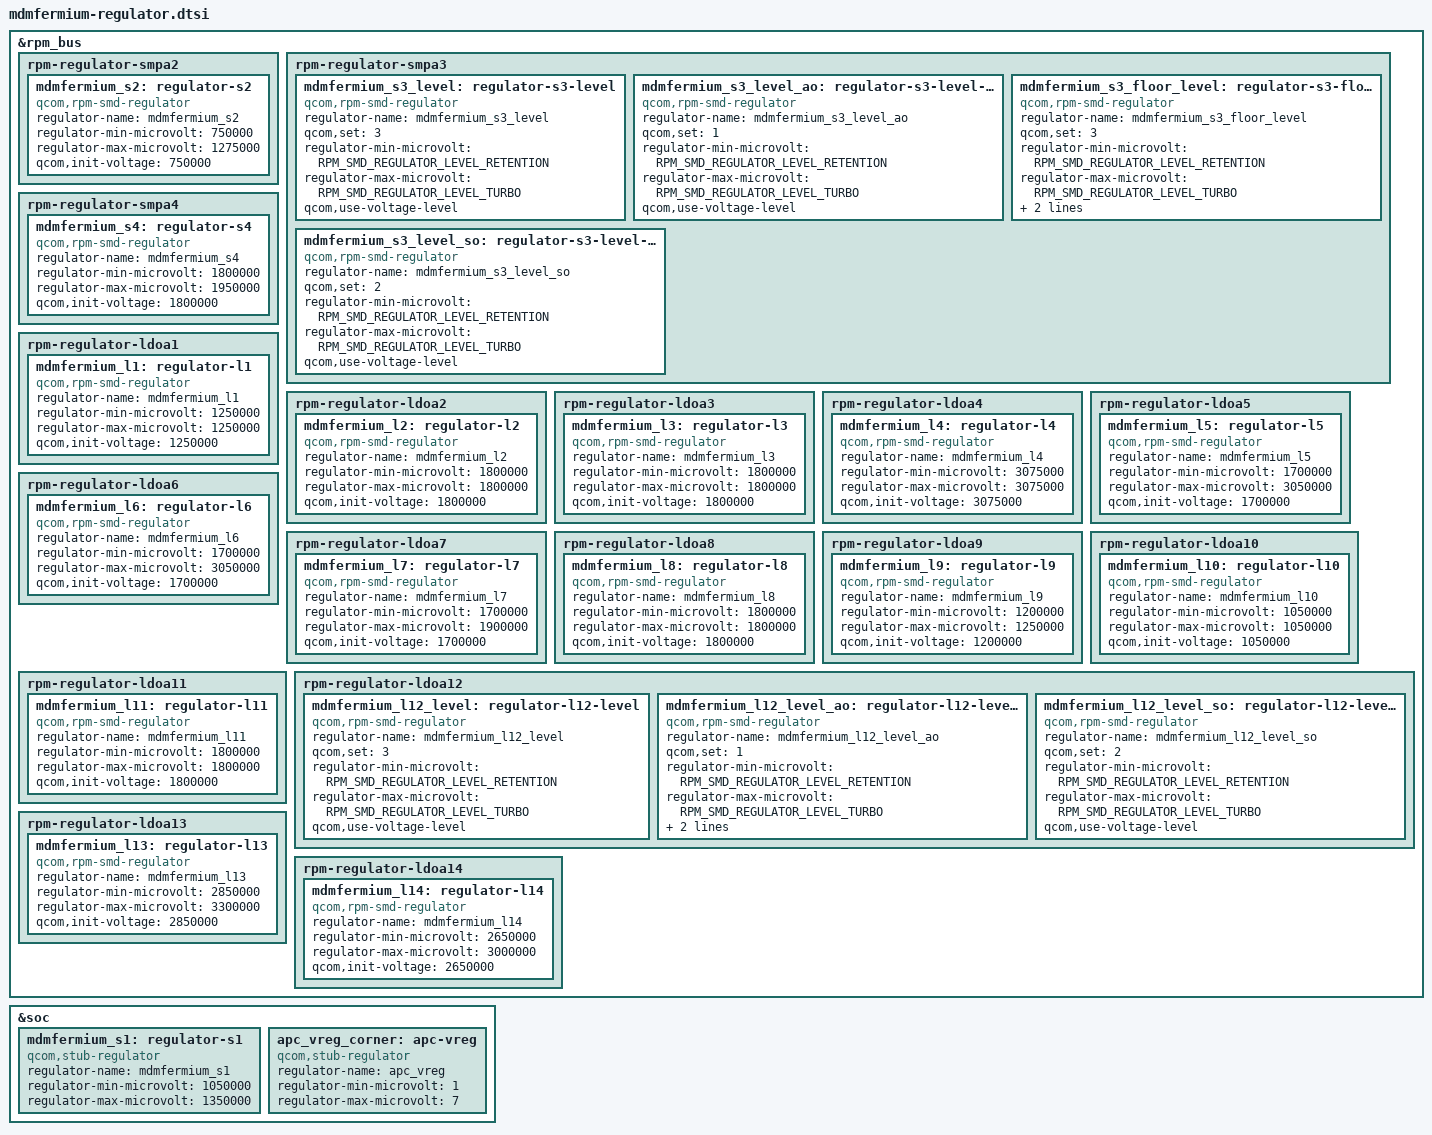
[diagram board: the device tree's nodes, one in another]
/* Copyright (c) 2015, The Linux Foundation. All rights reserved.
 *
 * This program is free software; you can redistribute it and/or modify
 * it under the terms of the GNU General Public License version 2 and
 * only version 2 as published by the Free Software Foundation.
 *
 * This program is distributed in the hope that it will be useful,
 * but WITHOUT ANY WARRANTY; without even the implied warranty of
 * MERCHANTABILITY or FITNESS FOR A PARTICULAR PURPOSE.  See the
 * GNU General Public License for more details.
 */

&rpm_bus {
	rpm-regulator-smpa2 {
		status = "okay";
		mdmfermium_s2: regulator-s2 {
			compatible = "qcom,rpm-smd-regulator";
			regulator-name = "mdmfermium_s2";
			regulator-min-microvolt = <750000>;
			regulator-max-microvolt = <1275000>;
			qcom,init-voltage = <750000>;
			status = "okay";
		};
	};

	/* CX supply */
	rpm-regulator-smpa3 {
		status = "okay";
		mdmfermium_s3_level: regulator-s3-level {
			compatible = "qcom,rpm-smd-regulator";
			regulator-name = "mdmfermium_s3_level";
			qcom,set = <3>;
			regulator-min-microvolt =
					<RPM_SMD_REGULATOR_LEVEL_RETENTION>;
			regulator-max-microvolt =
					<RPM_SMD_REGULATOR_LEVEL_TURBO>;
			qcom,use-voltage-level;
		};

		mdmfermium_s3_level_ao: regulator-s3-level-ao {
			compatible = "qcom,rpm-smd-regulator";
			regulator-name = "mdmfermium_s3_level_ao";
			qcom,set = <1>;
			regulator-min-microvolt =
					<RPM_SMD_REGULATOR_LEVEL_RETENTION>;
			regulator-max-microvolt =
					<RPM_SMD_REGULATOR_LEVEL_TURBO>;
			qcom,use-voltage-level;
		};

		mdmfermium_s3_floor_level: regulator-s3-floor-level {
			compatible = "qcom,rpm-smd-regulator";
			regulator-name = "mdmfermium_s3_floor_level";
			qcom,set = <3>;
			regulator-min-microvolt =
					<RPM_SMD_REGULATOR_LEVEL_RETENTION>;
			regulator-max-microvolt =
					<RPM_SMD_REGULATOR_LEVEL_TURBO>;
			qcom,use-voltage-floor-level;
			qcom,always-send-voltage;
		};

		mdmfermium_s3_level_so: regulator-s3-level-so {
			compatible = "qcom,rpm-smd-regulator";
			regulator-name = "mdmfermium_s3_level_so";
			qcom,set = <2>;
			regulator-min-microvolt =
					<RPM_SMD_REGULATOR_LEVEL_RETENTION>;
			regulator-max-microvolt =
					<RPM_SMD_REGULATOR_LEVEL_TURBO>;
			qcom,use-voltage-level;
		};
	};

	rpm-regulator-smpa4 {
		status = "okay";
		mdmfermium_s4: regulator-s4 {
			compatible = "qcom,rpm-smd-regulator";
			regulator-name = "mdmfermium_s4";
			regulator-min-microvolt = <1800000>;
			regulator-max-microvolt = <1950000>;
			qcom,init-voltage = <1800000>;
			status = "okay";
		};
	};

	rpm-regulator-ldoa1 {
		status = "okay";
		mdmfermium_l1: regulator-l1 {
			compatible = "qcom,rpm-smd-regulator";
			regulator-name = "mdmfermium_l1";
			regulator-min-microvolt = <1250000>;
			regulator-max-microvolt = <1250000>;
			qcom,init-voltage = <1250000>;
			status = "okay";
		};
	};

	rpm-regulator-ldoa2 {
		status = "okay";
		mdmfermium_l2: regulator-l2 {
			compatible = "qcom,rpm-smd-regulator";
			regulator-name = "mdmfermium_l2";
			regulator-min-microvolt = <1800000>;
			regulator-max-microvolt = <1800000>;
			qcom,init-voltage = <1800000>;
			status = "okay";
		};
	};

	rpm-regulator-ldoa3 {
		status = "okay";
		mdmfermium_l3: regulator-l3 {
			compatible = "qcom,rpm-smd-regulator";
			regulator-name = "mdmfermium_l3";
			regulator-min-microvolt = <1800000>;
			regulator-max-microvolt = <1800000>;
			qcom,init-voltage = <1800000>;
			status = "okay";
		};
	};

	rpm-regulator-ldoa4 {
		status = "okay";
		mdmfermium_l4: regulator-l4 {
			compatible = "qcom,rpm-smd-regulator";
			regulator-name = "mdmfermium_l4";
			regulator-min-microvolt = <3075000>;
			regulator-max-microvolt = <3075000>;
			qcom,init-voltage = <3075000>;
			status = "okay";
		};
	};

	rpm-regulator-ldoa5 {
		status = "okay";
		mdmfermium_l5: regulator-l5 {
			compatible = "qcom,rpm-smd-regulator";
			regulator-name = "mdmfermium_l5";
			regulator-min-microvolt = <1700000>;
			regulator-max-microvolt = <3050000>;
			qcom,init-voltage = <1700000>;
			status = "okay";
		};
	};

	rpm-regulator-ldoa6 {
		status = "okay";
		mdmfermium_l6: regulator-l6 {
			compatible = "qcom,rpm-smd-regulator";
			regulator-name = "mdmfermium_l6";
			regulator-min-microvolt = <1700000>;
			regulator-max-microvolt = <3050000>;
			qcom,init-voltage = <1700000>;
			status = "okay";
		};
	};

	rpm-regulator-ldoa7 {
		status = "okay";
		mdmfermium_l7: regulator-l7 {
			compatible = "qcom,rpm-smd-regulator";
			regulator-name = "mdmfermium_l7";
			regulator-min-microvolt = <1700000>;
			regulator-max-microvolt = <1900000>;
			qcom,init-voltage = <1700000>;
			status = "okay";
		};
	};

	rpm-regulator-ldoa8 {
		status = "okay";
		mdmfermium_l8: regulator-l8 {
			compatible = "qcom,rpm-smd-regulator";
			regulator-name = "mdmfermium_l8";
			regulator-min-microvolt = <1800000>;
			regulator-max-microvolt = <1800000>;
			qcom,init-voltage = <1800000>;
			status = "okay";
		};
	};

	rpm-regulator-ldoa9 {
		status = "okay";
		mdmfermium_l9: regulator-l9 {
			compatible = "qcom,rpm-smd-regulator";
			regulator-name = "mdmfermium_l9";
			regulator-min-microvolt = <1200000>;
			regulator-max-microvolt = <1250000>;
			qcom,init-voltage = <1200000>;
			status = "okay";
		};
	};

	rpm-regulator-ldoa10 {
		status = "okay";
		mdmfermium_l10: regulator-l10 {
			compatible = "qcom,rpm-smd-regulator";
			regulator-name = "mdmfermium_l10";
			regulator-min-microvolt = <1050000>;
			regulator-max-microvolt = <1050000>;
			qcom,init-voltage = <1050000>;
			status = "okay";
		};
	};

	rpm-regulator-ldoa11 {
		status = "okay";
		mdmfermium_l11: regulator-l11 {
			compatible = "qcom,rpm-smd-regulator";
			regulator-name = "mdmfermium_l11";
			regulator-min-microvolt = <1800000>;
			regulator-max-microvolt = <1800000>;
			qcom,init-voltage = <1800000>;
			status = "okay";
		};
	};

	/* MX supply */
	rpm-regulator-ldoa12 {
		status = "okay";
		mdmfermium_l12_level: regulator-l12-level {
			compatible = "qcom,rpm-smd-regulator";
			regulator-name = "mdmfermium_l12_level";
			qcom,set = <3>;
			regulator-min-microvolt =
					<RPM_SMD_REGULATOR_LEVEL_RETENTION>;
			regulator-max-microvolt =
					<RPM_SMD_REGULATOR_LEVEL_TURBO>;
			qcom,use-voltage-level;
		};

		mdmfermium_l12_level_ao: regulator-l12-level-ao {
			compatible = "qcom,rpm-smd-regulator";
			regulator-name = "mdmfermium_l12_level_ao";
			qcom,set = <1>;
			regulator-min-microvolt =
					<RPM_SMD_REGULATOR_LEVEL_RETENTION>;
			regulator-max-microvolt =
					<RPM_SMD_REGULATOR_LEVEL_TURBO>;
			qcom,use-voltage-level;
			qcom,always-send-voltage;
		};

		mdmfermium_l12_level_so: regulator-l12-level-so {
			compatible = "qcom,rpm-smd-regulator";
			regulator-name = "mdmfermium_l12_level_so";
			qcom,set = <2>;
			regulator-min-microvolt =
					<RPM_SMD_REGULATOR_LEVEL_RETENTION>;
			regulator-max-microvolt =
					<RPM_SMD_REGULATOR_LEVEL_TURBO>;
			qcom,use-voltage-level;
		};
	};

	rpm-regulator-ldoa13 {
		status = "okay";
		mdmfermium_l13: regulator-l13 {
			compatible = "qcom,rpm-smd-regulator";
			regulator-name = "mdmfermium_l13";
			regulator-min-microvolt = <2850000>;
			regulator-max-microvolt = <3300000>;
			qcom,init-voltage = <2850000>;
			status = "okay";
		};
	};

	rpm-regulator-ldoa14 {
		status = "okay";
		mdmfermium_l14: regulator-l14 {
			compatible = "qcom,rpm-smd-regulator";
			regulator-name = "mdmfermium_l14";
			regulator-min-microvolt = <2650000>;
			regulator-max-microvolt = <3000000>;
			qcom,init-voltage = <2650000>;
			status = "okay";
		};
	};
};

&soc {
	/* VDD APC supply */
	/* TODO: move to SPM controlled regulator */
	mdmfermium_s1: regulator-s1 {
		compatible = "qcom,stub-regulator";
		regulator-name = "mdmfermium_s1";
		regulator-min-microvolt = <1050000>;
		regulator-max-microvolt = <1350000>;
	};

	/* TODO: move to CPR regulator */
	apc_vreg_corner: apc-vreg {
		compatible = "qcom,stub-regulator";
		regulator-name = "apc_vreg";
		regulator-min-microvolt = <1>;
		regulator-max-microvolt = <7>;
	};
};
